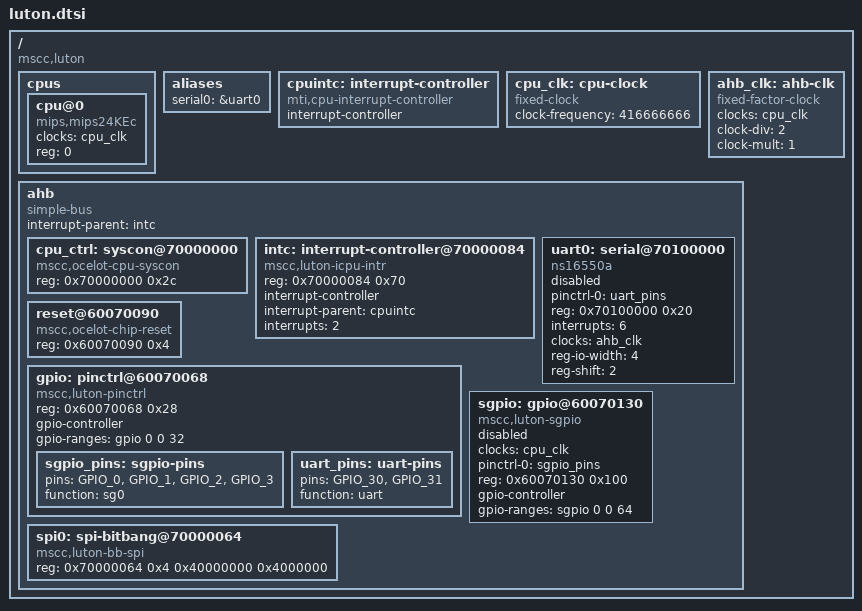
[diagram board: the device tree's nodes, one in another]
// SPDX-License-Identifier: (GPL-2.0+ OR MIT)
/*
 * Copyright (c) 2018 Microsemi Corporation
 */

#include <dt-bindings/gpio/gpio.h>

/ {
	#address-cells = <1>;
	#size-cells = <1>;
	compatible = "mscc,luton";

	cpus {
		#address-cells = <1>;
		#size-cells = <0>;

		cpu@0 {
			compatible = "mips,mips24KEc";
			device_type = "cpu";
			clocks = <&cpu_clk>;
			reg = <0>;
		};
	};

	aliases {
		serial0 = &uart0;
	};

	cpuintc: interrupt-controller {
		#address-cells = <0>;
		#interrupt-cells = <1>;
		interrupt-controller;
		compatible = "mti,cpu-interrupt-controller";
	};

	cpu_clk: cpu-clock {
		compatible = "fixed-clock";
		#clock-cells = <0>;
		clock-frequency = <416666666>;
	};

	ahb_clk: ahb-clk {
		compatible = "fixed-factor-clock";
		#clock-cells = <0>;
		clocks = <&cpu_clk>;
		clock-div = <2>;
		clock-mult = <1>;
	};

	ahb {
		compatible = "simple-bus";
		#address-cells = <1>;
		#size-cells = <1>;
		ranges;

		interrupt-parent = <&intc>;

		cpu_ctrl: syscon@70000000 {
			compatible = "mscc,ocelot-cpu-syscon", "syscon";
			reg = <0x70000000 0x2c>;
		};

		intc: interrupt-controller@70000084 {
			compatible = "mscc,luton-icpu-intr";
			reg = <0x70000084 0x70>;
			#interrupt-cells = <1>;
			interrupt-controller;
			interrupt-parent = <&cpuintc>;
			interrupts = <2>;
		};

		uart0: serial@70100000 {
			pinctrl-0 = <&uart_pins>;
			pinctrl-names = "default";
			compatible = "ns16550a";
			reg = <0x70100000 0x20>;
			interrupts = <6>;
			clocks = <&ahb_clk>;
			reg-io-width = <4>;
			reg-shift = <2>;

			status = "disabled";
		};

		reset@60070090 {
			compatible = "mscc,ocelot-chip-reset";
			reg = <0x60070090 0x4>;
		};

		gpio: pinctrl@60070068 {
			compatible = "mscc,luton-pinctrl";
			reg = <0x60070068 0x28>;
			gpio-controller;
			#gpio-cells = <2>;
			gpio-ranges = <&gpio 0 0 32>;

			sgpio_pins: sgpio-pins {
				pins = "GPIO_0", "GPIO_1", "GPIO_2", "GPIO_3";
				function = "sg0";
			};
			uart_pins: uart-pins {
				pins = "GPIO_30", "GPIO_31";
				function = "uart";
			};
		};

		sgpio: gpio@60070130 {
			compatible = "mscc,luton-sgpio";
			status = "disabled";
			clocks = <&cpu_clk>;
			pinctrl-0 = <&sgpio_pins>;
			pinctrl-names = "default";
			reg = <0x60070130 0x100>;
			gpio-controller;
			#gpio-cells = <2>;
			gpio-ranges = <&sgpio 0 0 64>;
		};

		spi0: spi-bitbang@70000064 {
			compatible = "mscc,luton-bb-spi";
			status = "okay";
			reg = <0x70000064 0x4 0x40000000 0x4000000>;
			#address-cells = <1>;
			#size-cells = <0>;
		};
	};
};
